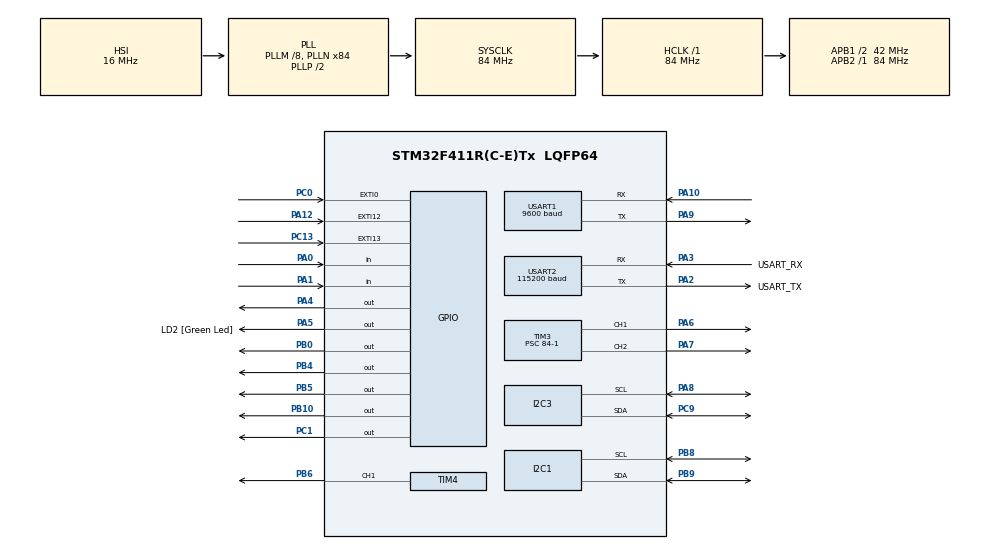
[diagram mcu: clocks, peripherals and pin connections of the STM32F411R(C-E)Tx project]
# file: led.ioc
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ADC1.Channel-0\#ChannelRegularConversion=ADC_CHANNEL_TEMPSENSOR
ADC1.NbrOfConversionFlag=1
ADC1.Rank-0\#ChannelRegularConversion=1
ADC1.SamplingTime-0\#ChannelRegularConversion=ADC_SAMPLETIME_3CYCLES
ADC1.master=1
Dma.ADC1.1.Direction=DMA_PERIPH_TO_MEMORY
Dma.ADC1.1.FIFOMode=DMA_FIFOMODE_DISABLE
Dma.ADC1.1.Instance=DMA2_Stream0
Dma.ADC1.1.MemDataAlignment=DMA_MDATAALIGN_WORD
Dma.ADC1.1.MemInc=DMA_MINC_ENABLE
Dma.ADC1.1.Mode=DMA_CIRCULAR
Dma.ADC1.1.PeriphDataAlignment=DMA_PDATAALIGN_WORD
Dma.ADC1.1.PeriphInc=DMA_PINC_DISABLE
Dma.ADC1.1.Priority=DMA_PRIORITY_LOW
Dma.I2C1_TX.2.Direction=DMA_MEMORY_TO_PERIPH
Dma.I2C1_TX.2.FIFOMode=DMA_FIFOMODE_DISABLE
Dma.I2C1_TX.2.Instance=DMA1_Stream1
Dma.I2C1_TX.2.MemDataAlignment=DMA_MDATAALIGN_BYTE
Dma.I2C1_TX.2.MemInc=DMA_MINC_ENABLE
Dma.I2C1_TX.2.Mode=DMA_NORMAL
Dma.I2C1_TX.2.PeriphDataAlignment=DMA_PDATAALIGN_BYTE
Dma.I2C1_TX.2.PeriphInc=DMA_PINC_DISABLE
Dma.I2C1_TX.2.Priority=DMA_PRIORITY_MEDIUM
Dma.I2C3_TX.3.Direction=DMA_MEMORY_TO_PERIPH
Dma.I2C3_TX.3.FIFOMode=DMA_FIFOMODE_DISABLE
Dma.I2C3_TX.3.Instance=DMA1_Stream4
Dma.I2C3_TX.3.MemDataAlignment=DMA_MDATAALIGN_BYTE
Dma.I2C3_TX.3.MemInc=DMA_MINC_ENABLE
Dma.I2C3_TX.3.Mode=DMA_NORMAL
Dma.I2C3_TX.3.PeriphDataAlignment=DMA_PDATAALIGN_BYTE
Dma.I2C3_TX.3.PeriphInc=DMA_PINC_DISABLE
Dma.I2C3_TX.3.Priority=DMA_PRIORITY_LOW
Dma.Request0=USART2_RX
Dma.Request1=ADC1
Dma.Request2=I2C1_TX
Dma.Request3=I2C3_TX
Dma.Request4=USART1_RX
Dma.Request5=USART1_TX
Dma.USART1_RX.4.Direction=DMA_PERIPH_TO_MEMORY
Dma.USART1_RX.4.FIFOMode=DMA_FIFOMODE_DISABLE
Dma.USART1_RX.4.Instance=DMA2_Stream2
Dma.USART1_RX.4.MemDataAlignment=DMA_MDATAALIGN_BYTE
Dma.USART1_RX.4.MemInc=DMA_MINC_ENABLE
Dma.USART1_RX.4.Mode=DMA_NORMAL
Dma.USART1_RX.4.PeriphDataAlignment=DMA_PDATAALIGN_BYTE
Dma.USART1_RX.4.PeriphInc=DMA_PINC_DISABLE
Dma.USART1_RX.4.Priority=DMA_PRIORITY_HIGH
Dma.USART1_TX.5.Direction=DMA_MEMORY_TO_PERIPH
Dma.USART1_TX.5.FIFOMode=DMA_FIFOMODE_DISABLE
Dma.USART1_TX.5.Instance=DMA2_Stream7
Dma.USART1_TX.5.MemDataAlignment=DMA_MDATAALIGN_BYTE
Dma.USART1_TX.5.MemInc=DMA_MINC_ENABLE
Dma.USART1_TX.5.Mode=DMA_NORMAL
Dma.USART1_TX.5.PeriphDataAlignment=DMA_PDATAALIGN_BYTE
Dma.USART1_TX.5.PeriphInc=DMA_PINC_DISABLE
Dma.USART1_TX.5.Priority=DMA_PRIORITY_HIGH
Dma.USART2_RX.0.Direction=DMA_PERIPH_TO_MEMORY
Dma.USART2_RX.0.FIFOMode=DMA_FIFOMODE_DISABLE
Dma.USART2_RX.0.Instance=DMA1_Stream5
Dma.USART2_RX.0.MemDataAlignment=DMA_MDATAALIGN_WORD
Dma.USART2_RX.0.MemInc=DMA_MINC_ENABLE
Dma.USART2_RX.0.Mode=DMA_CIRCULAR
Dma.USART2_RX.0.PeriphDataAlignment=DMA_PDATAALIGN_WORD
Dma.USART2_RX.0.PeriphInc=DMA_PINC_DISABLE
Dma.USART2_RX.0.Priority=DMA_PRIORITY_LOW
I2C1.I2C_Mode=I2C_Fast
Mcu.Family=STM32F4
Mcu.Name=STM32F411R(C-E)Tx
Mcu.Package=LQFP64
NVIC.DMA1_Stream1_IRQn=true\:0\:0\:false\:false\:true\:false\:true\:true
NVIC.DMA1_Stream4_IRQn=true\:0\:0\:false\:false\:true\:false\:true\:true
NVIC.DMA1_Stream5_IRQn=true\:0\:0\:false\:false\:true\:false\:true\:true
NVIC.DMA2_Stream0_IRQn=true\:0\:0\:false\:false\:true\:false\:true\:true
NVIC.DMA2_Stream2_IRQn=true\:0\:0\:false\:false\:true\:false\:true\:true
NVIC.DMA2_Stream7_IRQn=true\:0\:0\:false\:false\:true\:false\:true\:true
NVIC.EXTI0_IRQn=true\:0\:0\:false\:false\:true\:true\:true\:true
NVIC.EXTI15_10_IRQn=true\:0\:0\:false\:false\:true\:true\:true\:true
NVIC.I2C1_ER_IRQn=true\:0\:0\:false\:false\:true\:true\:true\:true
NVIC.I2C1_EV_IRQn=true\:0\:0\:false\:false\:true\:true\:true\:true
NVIC.I2C3_ER_IRQn=true\:0\:0\:false\:false\:true\:true\:true\:true
NVIC.I2C3_EV_IRQn=true\:0\:0\:false\:false\:true\:true\:true\:true
NVIC.PriorityGroup=NVIC_PRIORITYGROUP_0
NVIC.USART1_IRQn=true\:0\:0\:true\:false\:true\:true\:true\:true
NVIC.USART2_IRQn=true\:0\:0\:false\:false\:true\:true\:true\:true
PA0-WKUP.Signal=GPIO_Input
PA1.Signal=GPIO_Input
PA10.Mode=Asynchronous
PA10.Signal=USART1_RX
PA12.GPIO_ModeDefaultEXTI=GPIO_MODE_IT_FALLING
PA12.GPIO_PuPd=GPIO_PULLUP
PA12.Signal=GPXTI12
PA13.GPIO_Label=TMS
PA13.Mode=Serial_Wire
PA13.Signal=SYS_JTMS-SWDIO
PA14.GPIO_Label=TCK
PA14.Mode=Serial_Wire
PA14.Signal=SYS_JTCK-SWCLK
PA2.GPIO_Label=USART_TX
PA2.Mode=Asynchronous
PA2.Signal=USART2_TX
PA3.GPIO_Label=USART_RX
PA3.Mode=Asynchronous
PA3.Signal=USART2_RX
PA4.Signal=GPIO_Output
PA5.GPIO_Label=LD2 [Green Led]
PA5.GPIO_ModeDefaultOutputPP=GPIO_MODE_OUTPUT_PP
PA5.Signal=GPIO_Output
PA6.Signal=S_TIM3_CH1
PA7.Signal=S_TIM3_CH2
PA8.Mode=I2C
PA8.Signal=I2C3_SCL
PA9.Mode=Asynchronous
PA9.Signal=USART1_TX
PB0.Signal=GPIO_Output
PB10.Signal=GPIO_Output
PB3.Signal=SYS_JTDO-SWO
PB4.Signal=GPIO_Output
PB5.Signal=GPIO_Output
PB6.Signal=S_TIM4_CH1
PB8.Mode=I2C
PB8.Signal=I2C1_SCL
PB9.Mode=I2C
PB9.Signal=I2C1_SDA
PC0.GPIO_ModeDefaultEXTI=GPIO_MODE_IT_FALLING
PC0.Signal=GPXTI0
PC1.GPIO_ModeDefaultOutputPP=GPIO_MODE_OUTPUT_OD
PC1.GPIO_PuPd=GPIO_NOPULL
PC1.Signal=GPIO_Output
PC13-ANTI_TAMP.Signal=GPXTI13
PC14-OSC32_IN.Mode=LSE-External-Oscillator
PC14-OSC32_IN.Signal=RCC_OSC32_IN
PC15-OSC32_OUT.Mode=LSE-External-Oscillator
PC15-OSC32_OUT.Signal=RCC_OSC32_OUT
PC9.Mode=I2C
PC9.Signal=I2C3_SDA
PH0\ -\ OSC_IN.Mode=HSE-External-Clock-Source
PH0\ -\ OSC_IN.Signal=RCC_OSC_IN
PH1\ -\ OSC_OUT.Mode=HSE-External-Clock-Source
PH1\ -\ OSC_OUT.Signal=RCC_OSC_OUT
ProjectManager.HeapSize=0x200
ProjectManager.StackSize=0x400
ProjectManager.TargetToolchain=CMake
RCC.48MHZClocksFreq_Value=42000000
RCC.AHBFreq_Value=84000000
RCC.APB1CLKDivider=RCC_HCLK_DIV2
RCC.APB1Freq_Value=42000000
RCC.APB1TimFreq_Value=84000000
RCC.APB2Freq_Value=84000000
RCC.APB2TimFreq_Value=84000000
RCC.CortexFreq_Value=84000000
RCC.FLatency-AdvancedSettings=FLASH_LATENCY_2
RCC.HCLKFreq_Value=84000000
RCC.HSE_VALUE=8000000
RCC.HSI_VALUE=16000000
RCC.PLLM=8
RCC.PLLN=84
RCC.SYSCLKFreq_VALUE=84000000
RCC.SYSCLKSource=RCC_SYSCLKSOURCE_PLLCLK
RCC.VCOOutputFreq_Value=168000000
SH.S_TIM3_CH1.0=TIM3_CH1,PWM Generation1 CH1
SH.S_TIM3_CH2.0=TIM3_CH2,PWM Generation2 CH2
SH.S_TIM4_CH1.0=TIM4_CH1,PWM Generation1 CH1
TIM3.Channel-PWM\ Generation1\ CH1=TIM_CHANNEL_1
TIM3.Channel-PWM\ Generation2\ CH2=TIM_CHANNEL_2
TIM3.Period=1000-1
TIM3.Prescaler=84-1
TIM4.Channel-PWM\ Generation1\ CH1=TIM_CHANNEL_1
TIM4.Period=1000-1
TIM4.Prescaler=84-1
USART1.BaudRate=9600
USART1.VirtualMode=VM_ASYNC
USART2.BaudRate=115200
USART2.VirtualMode=VM_ASYNC
VP_ADC1_TempSens_Input.Mode=IN-TempSens
VP_TIM3_VS_ClockSourceINT.Mode=Internal
VP_TIM4_VS_ClockSourceINT.Mode=Internal
board=NUCLEO-F411RE

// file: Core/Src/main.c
/* USER CODE BEGIN Header */
/**
 ******************************************************************************
 * @file           : main.c
 * @brief          : Main program body
 ******************************************************************************
 * @attention
 *
 * Copyright (c) 2026 STMicroelectronics.
 * All rights reserved.
 *
 * This software is licensed under terms that can be found in the LICENSE file
 * in the root directory of this software component.
 * If no LICENSE file comes with this software, it is provided AS-IS.
 *
 ******************************************************************************
 */
/* USER CODE END Header */
#include "main.h"
#include "adc.h"
#include "dma.h"
#include "i2c.h"
#include "tim.h"
#include "usart.h"
#include "gpio.h"

/* USER CODE BEGIN Includes */
#include "apMain.h"

/* USER CODE END Includes */

void SystemClock_Config(void);

int main(void)
{

  /* MCU Configuration--------------------------------------------------------*/

  /* Reset of all peripherals, Initializes the Flash interface and the Systick. */
  HAL_Init();

  /* Configure the system clock */
  SystemClock_Config();

  /* Initialize all configured peripherals */
  MX_GPIO_Init();
  MX_DMA_Init();
  MX_USART2_UART_Init();
  MX_ADC1_Init();
  MX_I2C1_Init();
  MX_TIM3_Init();
  MX_TIM4_Init();
  MX_I2C3_Init();
  MX_USART1_UART_Init();
  /* USER CODE BEGIN 2 */
  apInit();
  apMain();

  /* USER CODE END 2 */

  /* Infinite loop */
  while (1) {

  }
}

void SystemClock_Config(void)
{
  RCC_OscInitTypeDef RCC_OscInitStruct = {0};
  RCC_ClkInitTypeDef RCC_ClkInitStruct = {0};

  /** Configure the main internal regulator output voltage
  */
  __HAL_RCC_PWR_CLK_ENABLE();
  __HAL_PWR_VOLTAGESCALING_CONFIG(PWR_REGULATOR_VOLTAGE_SCALE1);

  /** Initializes the RCC Oscillators according to the specified parameters
  * in the RCC_OscInitTypeDef structure.
  */
  RCC_OscInitStruct.OscillatorType = RCC_OSCILLATORTYPE_HSI;
  RCC_OscInitStruct.HSIState = RCC_HSI_ON;
  RCC_OscInitStruct.HSICalibrationValue = RCC_HSICALIBRATION_DEFAULT;
  RCC_OscInitStruct.PLL.PLLState = RCC_PLL_ON;
  RCC_OscInitStruct.PLL.PLLSource = RCC_PLLSOURCE_HSI;
  RCC_OscInitStruct.PLL.PLLM = 8;
  RCC_OscInitStruct.PLL.PLLN = 84;
  RCC_OscInitStruct.PLL.PLLP = RCC_PLLP_DIV2;
  RCC_OscInitStruct.PLL.PLLQ = 4;
  if (HAL_RCC_OscConfig(&RCC_OscInitStruct) != HAL_OK)
  {
    Error_Handler();
  }

  /** Initializes the CPU, AHB and APB buses clocks
  */
  RCC_ClkInitStruct.ClockType = RCC_CLOCKTYPE_HCLK|RCC_CLOCKTYPE_SYSCLK
                              |RCC_CLOCKTYPE_PCLK1|RCC_CLOCKTYPE_PCLK2;
  RCC_ClkInitStruct.SYSCLKSource = RCC_SYSCLKSOURCE_PLLCLK;
  RCC_ClkInitStruct.AHBCLKDivider = RCC_SYSCLK_DIV1;
  RCC_ClkInitStruct.APB1CLKDivider = RCC_HCLK_DIV2;
  RCC_ClkInitStruct.APB2CLKDivider = RCC_HCLK_DIV1;

  if (HAL_RCC_ClockConfig(&RCC_ClkInitStruct, FLASH_LATENCY_2) != HAL_OK)
  {
    Error_Handler();
  }
}

void Error_Handler(void)
{
  __disable_irq();
  while (1) {
  }
}
#ifdef USE_FULL_ASSERT
/**
  * @brief  Reports the name of the source file and the source line number
  *         where the assert_param error has occurred.
  * @param  file: pointer to the source file name
  * @param  line: assert_param error line source number
  * @retval None
  */
void assert_failed(uint8_t *file, uint32_t line)
{
  /* USER CODE BEGIN 6 */
  /* User can add his own implementation to report the file name and line
     number, ex: printf("Wrong parameters value: file %s on line %d\r\n", file,
     line) */
  /* USER CODE END 6 */
}
#endif /* USE_FULL_ASSERT */
